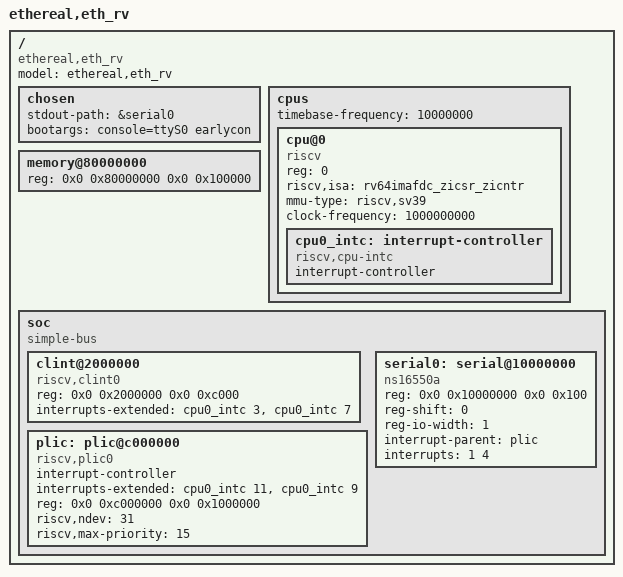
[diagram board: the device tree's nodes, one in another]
/* SPDX-License-Identifier: MIT
 *
 * eth_rv device tree (E2-RV2 increment 5, S3).
 *
 * This is the DT the harness hands to Spike with `--dtb=` and the one the
 * BootROM leaves in a1 (DTB_ADDR in the S3 contract). Its numbers are mirrored
 * by ethereal-shell/core.yaml and verif/eth_rv/rv_platform.py; the test
 * suite fails if the three disagree.
 *
 * Compile with:
 *   generated/rv_difftest/dtc/dtc -I dts -O dtb \
 *       -o generated/rv_difftest/eth_rv.dtb eth_rv.dts
 * or `python3 verif/eth_rv/build_dtb.py` (finds the built dtc for you).
 *
 * WHAT IS REAL HERE
 *   - memory @ 0x8000_0000, 1 MiB: the single window the TB, the AXI master and
 *     Spike's `-m0x80000000:1048576` all use (core.yaml ram_window_bytes).
 *   - clint @ 0x0200_0000, 0xc000: eth_rv_clint (msip/mtimecmp/mtime). Base and
 *     size match Spike's CLINT model exactly, so the golden and the DUT decode
 *     the same registers. It is the hart's M-mode timer/software source; an
 *     S-mode timer interrupt would have to be delegated and injected by firmware
 *     (`mideleg.STI` plus a `mip` write), which is why the node declares only
 *     the two M-mode lines — there is no S-mode timer source in this SoC.
 *   - serial @ 0x1000_0000: eth_rv_uart, register window and byte aliasing
 *     identical to Spike's ns16550 model (reg-shift 0, 1-byte registers). Its
 *     interrupt (source 1, level-triggered) is the PLIC's only connected source.
 *   - plic @ 0x0c00_0000, 16 MiB: eth_rv_plic (E2-RV2 increment 6), 31 sources,
 *     4-bit priorities, the `riscv,plic0` register map and Spike's base, size and
 *     source map. `interrupts-extended` gives each hart its M context (11) and
 *     then its S context (9), which is Spike's context order — so the S context
 *     is the hart's `mip.SEIP` and an S-mode kernel takes an external interrupt
 *     through `mideleg.SEI` with `scause = 9 | (1 << 63)`.
 *   - cpu @ 0: rv64imafdc_zicsr_zicntr (the MISATM value), Sv39, one hart.
 *
 * WHAT ELSE IS DELIBERATELY ABSENT (a DT that claims more changes what a kernel
 * is allowed to assume)
 *   - No cache properties, no Svadu/PBMTE, no Zicclsm: the core does not
 *     implement them (E2-RV2 G10/G11).
 *   - No `sstc`: the hart has no S-mode timer compare of its own, so a kernel must
 *     use the SBI timer (firmware writes `mtimecmp` and raises `mip.STIP`).
 *   - No IMSIC/APLIC nodes: this platform's controller is a PLIC, and Spike's
 *     AIA path is not enabled here.
 *   - Timebase and baud are DiffTest placeholders (the boundary below), so a
 *     kernel's `timebase-frequency`-derived delays and the UART's bit rate are
 *     out of contract until the board clock exists (E2-RV2 G9).
 *
 * BOUNDARY -- timebase-frequency and clock-frequency are DiffTest placeholders
 *   The CLINT advances mtime from the simulation cadence, not a board
 *   oscillator: Spike derives 10 MHz from CPU_HZ (1 GHz) / INSNS_PER_RTC_TICK
 *   (100), and our CLINT is driven on the same instruction cadence so both
 *   sides agree *while they run the same program*. `timebase-frequency` below
 *   records that DiffTest cadence. In SoC mode it must come from a real RTC
 *   tick input (E2-RV2 G9) -- until then, software that turns this number into
 *   seconds (sleeps, baud divisors, timer expiry) is out of contract.
 *   `clock-frequency` is likewise a placeholder, not a synthesis target.
 */

/dts-v1/;

/ {
	#address-cells = <2>;
	#size-cells = <2>;
	compatible = "ethereal,eth_rv";
	model = "ethereal,eth_rv";

	chosen {
		stdout-path = &serial0;
		bootargs = "console=ttyS0 earlycon";
	};

	cpus {
		#address-cells = <1>;
		#size-cells = <0>;
		timebase-frequency = <10000000>;

		cpu@0 {
			device_type = "cpu";
			compatible = "riscv";
			reg = <0>;
			status = "okay";
			riscv,isa = "rv64imafdc_zicsr_zicntr";
			mmu-type = "riscv,sv39";
			clock-frequency = <1000000000>;

			cpu0_intc: interrupt-controller {
				#interrupt-cells = <1>;
				interrupt-controller;
				compatible = "riscv,cpu-intc";
			};
		};
	};

	memory@80000000 {
		device_type = "memory";
		reg = <0x0 0x80000000 0x0 0x100000>;
	};

	soc {
		#address-cells = <2>;
		#size-cells = <2>;
		compatible = "simple-bus";
		ranges;

		clint@2000000 {
			compatible = "riscv,clint0";
			reg = <0x0 0x2000000 0x0 0xc000>;
			/* hart 0: MSIP (irq 3) and MTIP (irq 7) of the local interrupt
			 * controller. Both are M-mode lines: the S-mode timer is left to
			 * firmware (see "WHAT ELSE IS DELIBERATELY ABSENT"). */
			interrupts-extended = <&cpu0_intc 3 &cpu0_intc 7>;
		};

		/* E2-RV2 increment 6: real hardware (eth_rv_plic). Its M and S contexts
		 * are declared per hart in Spike's order, so the S context is the hart's
		 * `mip.SEIP`; the UART below is source 1 of it. */
		plic: plic@c000000 {
			compatible = "riscv,plic0";
			#address-cells = <0>;
			#interrupt-cells = <1>;
			interrupt-controller;
			interrupts-extended = <&cpu0_intc 11 &cpu0_intc 9>;
			reg = <0x0 0xc000000 0x0 0x1000000>;
			riscv,ndev = <31>;
			riscv,max-priority = <15>;
		};

		serial0: serial@10000000 {
			compatible = "ns16550a";
			reg = <0x0 0x10000000 0x0 0x100>;
			reg-shift = <0>;
			reg-io-width = <1>;
			/* Source 1, level-triggered (4): the register semantics the RTL
			 * mirrors are Spike's, and `cor_uart_rx`/`cor_plic` pin them. */
			interrupt-parent = <&plic>;
			interrupts = <1 4>;
		};
	};
};
